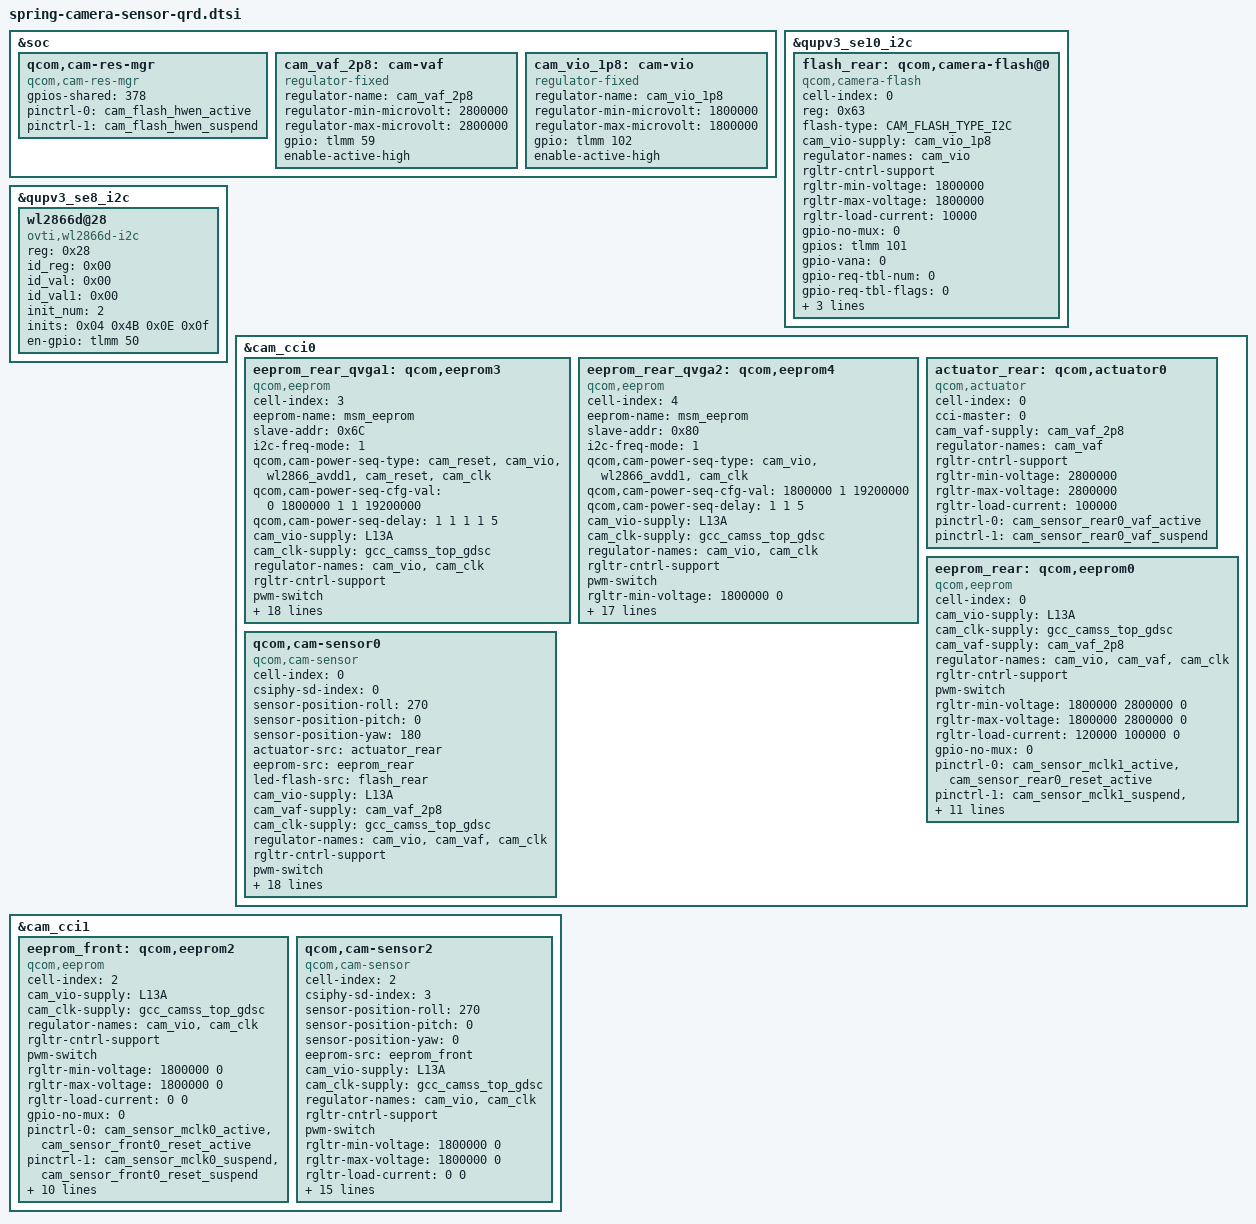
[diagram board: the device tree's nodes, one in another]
#include <dt-bindings/clock/qcom,gcc-blair.h>
#include <dt-bindings/msm-camera.h>

&soc {
	qcom,cam-res-mgr {
		compatible = "qcom,cam-res-mgr";
		status = "ok";
		gpios-shared = <378>;
		pinctrl-names = "cam_res_mgr_default", "cam_res_mgr_suspend";
		pinctrl-0 = <&cam_flash_hwen_active>;
		pinctrl-1 = <&cam_flash_hwen_suspend>;
	};

	cam_vaf_2p8: cam-vaf {
		compatible = "regulator-fixed";
		regulator-name = "cam_vaf_2p8";
		regulator-min-microvolt = <2800000>;
		regulator-max-microvolt = <2800000>;
		gpio = <&tlmm 59 0>;
		enable-active-high;
		status = "okay";
	};

	cam_vio_1p8: cam-vio {
		compatible = "regulator-fixed";
		regulator-name = "cam_vio_1p8";
		regulator-min-microvolt = <1800000>;
		regulator-max-microvolt = <1800000>;
		gpio = <&tlmm 102 0>;
		enable-active-high;
		status = "okay";
	};

/*

	flash_rear:qcom,camera-flash@0 {
		cell-index = <0>;
		compatible = "qcom,camera-flash";
		flash-type = <CAM_FLASH_TYPE_GPIO>;
		enm-gpio = <&tlmm 102 0>;
		enf-gpio = <&tlmm 101 0>;
		status = "ok";
	};
*/
};

&qupv3_se10_i2c {
	flash_rear:qcom,camera-flash@0 {
		cell-index = <0>;
		compatible = "qcom,camera-flash";
		reg = <0x63>;
		flash-type = <CAM_FLASH_TYPE_I2C>;
		cam_vio-supply = <&cam_vio_1p8>;
		regulator-names = "cam_vio";
		rgltr-cntrl-support;
		rgltr-min-voltage = <1800000>;
		rgltr-max-voltage = <1800000>;
		rgltr-load-current = <10000>;
		gpio-no-mux = <0>;
                gpios = <&tlmm 101 0>;
                gpio-vana = <0>;
                gpio-req-tbl-num = <0>;
                gpio-req-tbl-flags = <0>;
                gpio-req-tbl-label = "FLASH_ENM";
		//pinctrl-names = "cam_default", "cam_suspend";
		//pinctrl-0 = <&cam_flash_hwen_active>;
		//pinctrl-1 = <&cam_flash_hwen_suspend>;
		enm-gpio = <&tlmm 102 0>;
		enf-gpio = <&tlmm 101 0>;
		status = "ok";
	};
};

&qupv3_se8_i2c {
    status = "ok";
    wl2866d@28 {
        compatible = "ovti,wl2866d-i2c";
        reg = <0x28>;
        id_reg = <0x00>;
        id_val = <0x00>;
        id_val1 = <0x00>;
        init_num = <2>;
        inits = <0x04 0x4B 0x0E 0x0f>;
        en-gpio = <&tlmm 50 0>;
        status = "ok";
    };
};

&cam_cci0 {
    /* SC080CS */
	eeprom_rear_qvga1: qcom,eeprom3 {
		cell-index = <3>;
		compatible = "qcom,eeprom";
		eeprom-name = "msm_eeprom";
		slave-addr = <0x6C>;
		i2c-freq-mode = <1>;
		qcom,cam-power-seq-type = "cam_reset", "cam_vio", "wl2866_avdd1", "cam_reset", "cam_clk";
		qcom,cam-power-seq-cfg-val = <0 1800000 1 1 19200000>;
		qcom,cam-power-seq-delay = <1 1 1 1 5>;
		cam_vio-supply = <&L13A>;
		cam_clk-supply = <&gcc_camss_top_gdsc>;
		regulator-names = "cam_vio","cam_clk";
		rgltr-cntrl-support;
		pwm-switch;
		rgltr-min-voltage = <1800000 0>;
		rgltr-max-voltage = <1800000 0>;
		rgltr-load-current = <80000 0>;
		gpio-no-mux = <0>;
		pinctrl-names = "cam_default", "cam_suspend";
		pinctrl-0 = <&cam_sensor_mclk2_active
				&cam_sensor_rear2_reset_active>;
		pinctrl-1 = <&cam_sensor_mclk2_suspend
				&cam_sensor_rear2_reset_suspend>;
		gpios = <&tlmm 31 0>,
			<&tlmm 36 0>;
		gpio-reset = <1>;
		gpio-req-tbl-num = <0 1>;
		gpio-req-tbl-flags = <1 0>;
		gpio-req-tbl-label = "CAMIF_MCLK2",
					"CAM_RESET1";
		sensor-mode = <0>;
		cci-master = <1>;
		clocks = <&gcc GCC_CAMSS_MCLK2_CLK>;
		clock-names = "cam_clk";
		clock-cntl-level = "turbo";
		clock-rates = <19200000>;
		status = "ok";
	};

    /* GC6163B */
	eeprom_rear_qvga2: qcom,eeprom4 {
		cell-index = <4>;
		compatible = "qcom,eeprom";
		eeprom-name = "msm_eeprom";
		slave-addr = <0x80>;
		i2c-freq-mode = <1>;
		qcom,cam-power-seq-type = "cam_vio", "wl2866_avdd1", "cam_clk";
		qcom,cam-power-seq-cfg-val = <1800000 1 19200000>;
		qcom,cam-power-seq-delay = <1 1 5>;
		cam_vio-supply = <&L13A>;
		cam_clk-supply = <&gcc_camss_top_gdsc>;
		regulator-names = "cam_vio","cam_clk";
		rgltr-cntrl-support;
		pwm-switch;
		rgltr-min-voltage = <1800000 0>;
		rgltr-max-voltage = <1800000 0>;
		rgltr-load-current = <80000 0>;
		gpio-no-mux = <0>;
		pinctrl-names = "cam_default", "cam_suspend";
		pinctrl-0 = <&cam_sensor_mclk2_active
				&cam_sensor_rear2_reset_active>;
		pinctrl-1 = <&cam_sensor_mclk2_suspend
				&cam_sensor_rear2_reset_suspend>;
		gpios = <&tlmm 31 0>,
			<&tlmm 36 0>;
		gpio-reset = <1>;
		gpio-req-tbl-num = <0 1>;
		gpio-req-tbl-flags = <1 0>;
		gpio-req-tbl-label = "CAMIF_MCLK2",
					"CAM_RESET1";
		sensor-mode = <0>;
		cci-master = <1>;
		clocks = <&gcc GCC_CAMSS_MCLK2_CLK>;
		clock-names = "cam_clk";
		clock-cntl-level = "turbo";
		clock-rates = <19200000>;
		status = "ok";
	};

	actuator_rear: qcom,actuator0 {
		cell-index = <0>;
		compatible = "qcom,actuator";
		cci-master = <0>;
		cam_vaf-supply = <&cam_vaf_2p8>;
		regulator-names = "cam_vaf";
		rgltr-cntrl-support;
		rgltr-min-voltage = <2800000>;
		rgltr-max-voltage = <2800000>;
		rgltr-load-current = <100000>;
		pinctrl-names = "cam_default", "cam_suspend";
		pinctrl-0 = <&cam_sensor_rear0_vaf_active>;
		pinctrl-1 = <&cam_sensor_rear0_vaf_suspend>;
		status = "ok";
	};

	eeprom_rear: qcom,eeprom0 {
		cell-index = <0>;
		compatible = "qcom,eeprom";
		// cam_vana-supply = <&L4P>;
		// cam_vdig-supply = <&L2P>;
		cam_vio-supply = <&L13A>;
		cam_clk-supply = <&gcc_camss_top_gdsc>;
		cam_vaf-supply = <&cam_vaf_2p8>;
		regulator-names = "cam_vio", "cam_vaf", "cam_clk";
		rgltr-cntrl-support;
		pwm-switch;
		rgltr-min-voltage = <1800000 2800000 0>;
		rgltr-max-voltage = <1800000 2800000 0>;
		rgltr-load-current = <120000 100000 0>;
		gpio-no-mux = <0>;
		pinctrl-names = "cam_default", "cam_suspend";
		pinctrl-0 = <&cam_sensor_mclk1_active
				&cam_sensor_rear0_reset_active>;
		pinctrl-1 = <&cam_sensor_mclk1_suspend
				&cam_sensor_rear0_reset_suspend>;
		gpios = <&tlmm 30 0>,
			<&tlmm 34 0>;
		gpio-reset = <1>;
		gpio-req-tbl-num = <0 1>;
		gpio-req-tbl-flags = <1 0>;
		gpio-req-tbl-label = "CAMIF_MCLK1",
					"CAM_RESET0";
		sensor-mode = <0>;
		cci-master = <0>;
		status = "ok";
		clocks = <&gcc GCC_CAMSS_MCLK1_CLK>;
		clock-names = "cam_clk";
		clock-cntl-level = "turbo";
		clock-rates = <19200000>;
	};

	/* Rear*/
	qcom,cam-sensor0 {
		cell-index = <0>;
		compatible = "qcom,cam-sensor";
		csiphy-sd-index = <0>;
		sensor-position-roll = <270>;
		sensor-position-pitch = <0>;
		sensor-position-yaw = <180>;
		actuator-src = <&actuator_rear>;
		eeprom-src = <&eeprom_rear>;
		led-flash-src = <&flash_rear>;
		cam_vio-supply = <&L13A>;
		cam_vaf-supply = <&cam_vaf_2p8>;
		//cam_vana-supply = <&L4P>;
		//cam_vdig-supply = <&L2P>;
		cam_clk-supply = <&gcc_camss_top_gdsc>;
		regulator-names = "cam_vio", "cam_vaf", "cam_clk";
		rgltr-cntrl-support;
		pwm-switch;
		rgltr-min-voltage = <1800000 2800000 0>;
		rgltr-max-voltage = <1800000 2800000 0>;
		rgltr-load-current = <120000 100000 0>;
		gpio-no-mux = <0>;
		pinctrl-names = "cam_default", "cam_suspend";
		pinctrl-0 = <&cam_sensor_mclk1_active
				&cam_sensor_rear0_reset_active>;
		pinctrl-1 = <&cam_sensor_mclk1_suspend
				&cam_sensor_rear0_reset_suspend>;
		gpios = <&tlmm 30 0>,
			<&tlmm 34 0>;
		gpio-reset = <1>;
		gpio-req-tbl-num = <0 1>;
		gpio-req-tbl-flags = <1 0>;
		gpio-req-tbl-label = "CAMIF_MCLK1",
					"CAM_RESET0";
		sensor-mode = <0>;
		cci-master = <0>;
		status = "ok";
		clocks = <&gcc GCC_CAMSS_MCLK1_CLK>;
		clock-names = "cam_clk";
		clock-cntl-level = "turbo";
		clock-rates = <19200000>;
	};
};

&cam_cci1 {
	eeprom_front: qcom,eeprom2 {
		cell-index = <2>;
		compatible = "qcom,eeprom";
		cam_vio-supply = <&L13A>;
		//cam_vana-supply = <&L3P>;
		//cam_vdig-supply = <&L2P>;
		cam_clk-supply = <&gcc_camss_top_gdsc>;
		regulator-names = "cam_vio", "cam_clk";
		rgltr-cntrl-support;
		pwm-switch;
		rgltr-min-voltage = <1800000 0>;
		rgltr-max-voltage = <1800000 0>;
		rgltr-load-current = <0 0>;
		gpio-no-mux = <0>;
		pinctrl-names = "cam_default", "cam_suspend";
		pinctrl-0 = <&cam_sensor_mclk0_active
				&cam_sensor_front0_reset_active>;
		pinctrl-1 = <&cam_sensor_mclk0_suspend
				&cam_sensor_front0_reset_suspend>;
		gpios = <&tlmm 29 0>,
			<&tlmm 37 0>;
		gpio-reset = <1>;
		gpio-req-tbl-num = <0 1>;
		gpio-req-tbl-flags = <1 0>;
		gpio-req-tbl-label = "CAMIF_MCLK0",
					"CAM_RESET3";
		sensor-mode = <0>;
		cci-master = <0>;
		status = "ok";
		clocks = <&gcc GCC_CAMSS_MCLK0_CLK>;
		clock-names = "cam_clk";
		clock-cntl-level = "turbo";
		clock-rates = <19200000>;
	};

	/*Front*/
	qcom,cam-sensor2 {
		cell-index = <2>;
		compatible = "qcom,cam-sensor";
		csiphy-sd-index = <3>;
		sensor-position-roll = <270>;
		sensor-position-pitch = <0>;
		sensor-position-yaw = <0>;
		eeprom-src = <&eeprom_front>;
		cam_vio-supply = <&L13A>;
		//cam_vana-supply = <&L3P>;
		//cam_vdig-supply = <&L2P>;
		cam_clk-supply = <&gcc_camss_top_gdsc>;
		regulator-names = "cam_vio", "cam_clk";
		rgltr-cntrl-support;
		pwm-switch;
		rgltr-min-voltage = <1800000 0>;
		rgltr-max-voltage = <1800000 0>;
		rgltr-load-current = <0 0>;
		gpio-no-mux = <0>;
		pinctrl-names = "cam_default", "cam_suspend";
		pinctrl-0 = <&cam_sensor_mclk0_active
				&cam_sensor_front0_reset_active>;
		pinctrl-1 = <&cam_sensor_mclk0_suspend
				&cam_sensor_front0_reset_suspend>;
		gpios = <&tlmm 29 0>,
			<&tlmm 37 0>;
		gpio-reset = <1>;
		gpio-req-tbl-num = <0 1>;
		gpio-req-tbl-flags = <1 0>;
		gpio-req-tbl-label = "CAMIF_MCLK0",
					"CAM_RESET3";
		sensor-mode = <0>;
		cci-master = <0>;
		status = "ok";
		clocks = <&gcc GCC_CAMSS_MCLK0_CLK>;
		clock-names = "cam_clk";
		clock-cntl-level = "turbo";
		clock-rates = <19200000>;
	};
};
